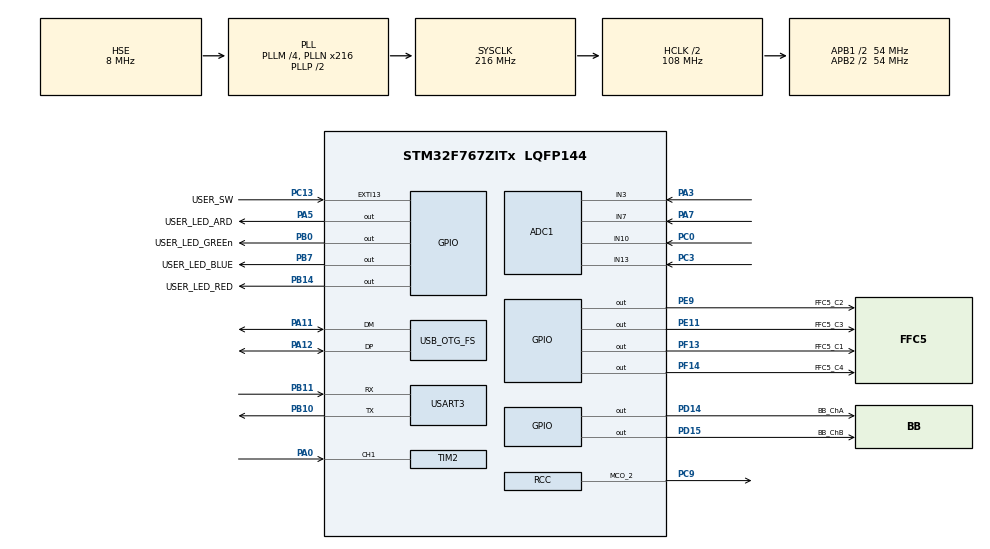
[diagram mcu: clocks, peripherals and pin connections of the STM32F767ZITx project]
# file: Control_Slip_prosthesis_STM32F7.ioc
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ADC1.Channel-0\#ChannelRegularConversion=ADC_CHANNEL_3
ADC1.Channel-4\#ChannelRegularConversion=ADC_CHANNEL_7
ADC1.Channel-5\#ChannelRegularConversion=ADC_CHANNEL_10
ADC1.Channel-6\#ChannelRegularConversion=ADC_CHANNEL_13
ADC1.ContinuousConvMode=ENABLE
ADC1.NbrOfConversion=4
ADC1.NbrOfConversionFlag=1
ADC1.Rank-0\#ChannelRegularConversion=1
ADC1.Rank-4\#ChannelRegularConversion=2
ADC1.Rank-5\#ChannelRegularConversion=3
ADC1.Rank-6\#ChannelRegularConversion=4
ADC1.SamplingTime-0\#ChannelRegularConversion=ADC_SAMPLETIME_480CYCLES
ADC1.SamplingTime-4\#ChannelRegularConversion=ADC_SAMPLETIME_480CYCLES
ADC1.SamplingTime-5\#ChannelRegularConversion=ADC_SAMPLETIME_480CYCLES
ADC1.SamplingTime-6\#ChannelRegularConversion=ADC_SAMPLETIME_480CYCLES
ADC1.ScanConvMode=ADC_SCAN_ENABLE
ADC1.master=1
Mcu.Family=STM32F7
Mcu.Name=STM32F767ZITx
Mcu.Package=LQFP144
NVIC.EXTI15_10_IRQn=true\:5\:0\:true\:false\:true\:true\:true
NVIC.OTG_FS_IRQn=true\:2\:0\:true\:false\:true\:true\:true
NVIC.PriorityGroup=NVIC_PRIORITYGROUP_4
NVIC.TIM1_UP_TIM10_IRQn=true\:2\:0\:true\:false\:true\:true\:true
NVIC.USART3_IRQn=true\:2\:0\:true\:false\:true\:true\:true
PA0/WKUP.Signal=S_TIM2_CH1_ETR
PA1.Signal=ADCx_IN1
PA11.Mode=Device_Only
PA11.Signal=USB_OTG_FS_DM
PA12.Mode=Device_Only
PA12.Signal=USB_OTG_FS_DP
PA13.Mode=Serial_Wire
PA13.Signal=SYS_JTMS-SWDIO
PA14.Mode=Serial_Wire
PA14.Signal=SYS_JTCK-SWCLK
PA3.Signal=ADCx_IN3
PA5.GPIO_Label=USER_LED_ARD
PA5.GPIO_Speed=GPIO_SPEED_FREQ_VERY_HIGH
PA5.PinState=GPIO_PIN_RESET
PA5.Signal=GPIO_Output
PA7.Signal=ADCx_IN7
PB0.GPIO_Label=USER_LED_GREEn
PB0.GPIO_Speed=GPIO_SPEED_FREQ_VERY_HIGH
PB0.Signal=GPIO_Output
PB10.Mode=Asynchronous
PB10.Signal=USART3_TX
PB11.Mode=Asynchronous
PB11.Signal=USART3_RX
PB14.GPIO_Label=USER_LED_RED
PB14.GPIO_Speed=GPIO_SPEED_FREQ_VERY_HIGH
PB14.Signal=GPIO_Output
PB7.GPIO_Label=USER_LED_BLUE
PB7.GPIO_Speed=GPIO_SPEED_FREQ_VERY_HIGH
PB7.Signal=GPIO_Output
PC0.Signal=ADCx_IN10
PC13.GPIO_Label=USER_SW
PC13.GPIO_ModeDefaultEXTI=GPIO_MODE_IT_FALLING
PC13.GPIO_PuPd=GPIO_NOPULL
PC13.Signal=GPXTI13
PC14/OSC32_IN.Mode=LSE-External-Oscillator
PC14/OSC32_IN.Signal=RCC_OSC32_IN
PC15/OSC32_OUT.Mode=LSE-External-Oscillator
PC15/OSC32_OUT.Signal=RCC_OSC32_OUT
PC3.Signal=ADCx_IN13
PC9.Mode=Clock-out-2
PC9.Signal=RCC_MCO_2
PD14.GPIO_Label=BB_ChA
PD14.Signal=GPIO_Output
PD15.GPIO_Label=BB_ChB
PD15.Signal=GPIO_Output
PE11.GPIO_Label=FFC5_C3
PE11.GPIO_Speed=GPIO_SPEED_FREQ_HIGH
PE11.Signal=GPIO_Output
PE9.GPIO_Label=FFC5_C2
PE9.GPIO_Speed=GPIO_SPEED_FREQ_HIGH
PE9.Signal=GPIO_Output
PF13.GPIO_Label=FFC5_C1
PF13.GPIO_Speed=GPIO_SPEED_FREQ_HIGH
PF13.Signal=GPIO_Output
PF14.GPIO_Label=FFC5_C4
PF14.GPIO_Speed=GPIO_SPEED_FREQ_HIGH
PF14.Signal=GPIO_Output
PH0/OSC_IN.Mode=HSE-External-Clock-Source
PH0/OSC_IN.Signal=RCC_OSC_IN
PH1/OSC_OUT.Mode=HSE-External-Clock-Source
PH1/OSC_OUT.Signal=RCC_OSC_OUT
ProjectManager.HeapSize=0x200
ProjectManager.StackSize=0x400
ProjectManager.TargetToolchain=STM32CubeIDE
RCC.AHBCLKDivider=RCC_SYSCLK_DIV2
RCC.AHBFreq_Value=108000000
RCC.APB1CLKDivider=RCC_HCLK_DIV2
RCC.APB1Freq_Value=54000000
RCC.APB1TimFreq_Value=108000000
RCC.APB2CLKDivider=RCC_HCLK_DIV2
RCC.APB2Freq_Value=54000000
RCC.APB2TimFreq_Value=108000000
RCC.CortexFreq_Value=108000000
RCC.HCLKFreq_Value=108000000
RCC.HSE_VALUE=8000000
RCC.HSI_VALUE=16000000
RCC.PLLM=4
RCC.PLLN=216
RCC.PLLQ=9
RCC.RCC_MCO2Source=RCC_MCO2SOURCE_PLLCLK
RCC.RCC_MCODiv1=RCC_MCODIV_4
RCC.RCC_MCODiv2=RCC_MCODIV_5
RCC.SYSCLKFreq_VALUE=216000000
RCC.SYSCLKSource=RCC_SYSCLKSOURCE_PLLCLK
RCC.USBFreq_Value=48000000
RCC.VCOOutputFreq_Value=432000000
SH.ADCx_IN1.0=ADC1_IN1
SH.ADCx_IN10.0=ADC1_IN10,IN10
SH.ADCx_IN13.0=ADC1_IN13,IN13
SH.ADCx_IN3.0=ADC1_IN3,IN3
SH.ADCx_IN7.0=ADC1_IN7,IN7
SH.S_TIM2_CH1_ETR.0=TIM2_CH1,Input_Capture1_from_TI1
TIM1.Period=2-1
TIM1.Prescaler=54000-1
TIM2.Channel-Input_Capture1_from_TI1=TIM_CHANNEL_1
TIM2.Period=255
TIM2.Prescaler=143
USART3.VirtualMode-Asynchronous=VM_ASYNC
USB_DEVICE.CLASS_NAME_FS=CDC
USB_DEVICE.VirtualMode-CDC_FS=Cdc
USB_DEVICE.VirtualModeFS=Cdc_FS
USB_OTG_FS.VirtualMode=Device_Only
VP_TIM1_VS_ClockSourceINT.Mode=Internal
VP_USB_DEVICE_VS_USB_DEVICE_CDC_FS.Mode=CDC_FS
board=custom

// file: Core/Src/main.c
/* USER CODE BEGIN Header */
/**
 ******************************************************************************
 * @file           : main.c
 * @brief          : Main program body
 ******************************************************************************
 * @attention
 *
 * <h2><center>&copy; Copyright (c) 2021 STMicroelectronics.
 * All rights reserved.</center></h2>
 *
 * This software component is licensed by ST under BSD 3-Clause license,
 * the "License"; You may not use this file except in compliance with the
 * License. You may obtain a copy of the License at:
 *                        opensource.org/licenses/BSD-3-Clause
 *
 ******************************************************************************
 */
/* USER CODE END Header */
#include "main.h"
#include "usb_device.h"

/* USER CODE BEGIN Includes */
#include "app.h"
#include "definitions.h"
#include "bebionic.h"
/* USER CODE END Includes */

ADC_HandleTypeDef hadc1;

TIM_HandleTypeDef htim1;
TIM_HandleTypeDef htim2;

UART_HandleTypeDef huart3;

void SystemClock_Config(void);
static void MX_GPIO_Init(void);
static void MX_USART3_UART_Init(void);
static void MX_TIM1_Init(void);
static void MX_ADC1_Init(void);
static void MX_TIM2_Init(void);

int main(void)
{

  /* MCU Configuration--------------------------------------------------------*/

  /* Reset of all peripherals, Initializes the Flash interface and the Systick. */
  HAL_Init();

  /* Configure the system clock */
  SystemClock_Config();

  /* Initialize all configured peripherals */
  MX_GPIO_Init();
  MX_USART3_UART_Init();
  MX_TIM1_Init();
  MX_ADC1_Init();
  MX_USB_DEVICE_Init();
  MX_TIM2_Init();
  /* USER CODE BEGIN 2 */
  app_init(); // Funções de inicialização na pasta app para não misturar

  /* USER CODE END 2 */

  /* Infinite loop */
  /* USER CODE BEGIN WHILE */
  while (1)
  {
	app_controle_bebionic(); // teste para controle da prótese
    // app_loop(); // Funções do loop na pasta app para não misturar
    /* USER CODE END WHILE */

    /* USER CODE BEGIN 3 */
    /*
    HAL_GPIO_TogglePin(GPIOA, GPIO_PIN_5);
    HAL_Delay(1);
    HAL_GPIO_TogglePin(GPIOB, GPIO_PIN_0);
        //HAL_Delay(200);
      HAL_GPIO_TogglePin(GPIOB, GPIO_PIN_7);
         // HAL_Delay(200);
        HAL_GPIO_TogglePin(GPIOB, GPIO_PIN_14);
           // HAL_Delay(200);
        */
  }
  /* USER CODE END 3 */
}

void SystemClock_Config(void)
{
  RCC_OscInitTypeDef RCC_OscInitStruct = {0};
  RCC_ClkInitTypeDef RCC_ClkInitStruct = {0};
  RCC_PeriphCLKInitTypeDef PeriphClkInitStruct = {0};

  /** Configure LSE Drive Capability
  */
  HAL_PWR_EnableBkUpAccess();
  /** Configure the main internal regulator output voltage
  */
  __HAL_RCC_PWR_CLK_ENABLE();
  __HAL_PWR_VOLTAGESCALING_CONFIG(PWR_REGULATOR_VOLTAGE_SCALE3);
  /** Initializes the RCC Oscillators according to the specified parameters
  * in the RCC_OscInitTypeDef structure.
  */
  RCC_OscInitStruct.OscillatorType = RCC_OSCILLATORTYPE_HSE;
  RCC_OscInitStruct.HSEState = RCC_HSE_BYPASS;
  RCC_OscInitStruct.PLL.PLLState = RCC_PLL_ON;
  RCC_OscInitStruct.PLL.PLLSource = RCC_PLLSOURCE_HSE;
  RCC_OscInitStruct.PLL.PLLM = 4;
  RCC_OscInitStruct.PLL.PLLN = 216;
  RCC_OscInitStruct.PLL.PLLP = RCC_PLLP_DIV2;
  RCC_OscInitStruct.PLL.PLLQ = 9;
  RCC_OscInitStruct.PLL.PLLR = 2;
  if (HAL_RCC_OscConfig(&RCC_OscInitStruct) != HAL_OK)
  {
    Error_Handler();
  }
  /** Activate the Over-Drive mode
  */
  if (HAL_PWREx_EnableOverDrive() != HAL_OK)
  {
    Error_Handler();
  }
  /** Initializes the CPU, AHB and APB buses clocks
  */
  RCC_ClkInitStruct.ClockType = RCC_CLOCKTYPE_HCLK|RCC_CLOCKTYPE_SYSCLK
                              |RCC_CLOCKTYPE_PCLK1|RCC_CLOCKTYPE_PCLK2;
  RCC_ClkInitStruct.SYSCLKSource = RCC_SYSCLKSOURCE_PLLCLK;
  RCC_ClkInitStruct.AHBCLKDivider = RCC_SYSCLK_DIV2;
  RCC_ClkInitStruct.APB1CLKDivider = RCC_HCLK_DIV2;
  RCC_ClkInitStruct.APB2CLKDivider = RCC_HCLK_DIV2;

  if (HAL_RCC_ClockConfig(&RCC_ClkInitStruct, FLASH_LATENCY_3) != HAL_OK)
  {
    Error_Handler();
  }
  PeriphClkInitStruct.PeriphClockSelection = RCC_PERIPHCLK_USART3|RCC_PERIPHCLK_CLK48;
  PeriphClkInitStruct.Usart3ClockSelection = RCC_USART3CLKSOURCE_PCLK1;
  PeriphClkInitStruct.Clk48ClockSelection = RCC_CLK48SOURCE_PLL;
  if (HAL_RCCEx_PeriphCLKConfig(&PeriphClkInitStruct) != HAL_OK)
  {
    Error_Handler();
  }
  HAL_RCC_MCOConfig(RCC_MCO2, RCC_MCO2SOURCE_PLLCLK, RCC_MCODIV_5);
}

static void MX_ADC1_Init(void)
{

  ADC_ChannelConfTypeDef sConfig = {0};

  /* USER CODE BEGIN ADC1_Init 1 */
  //--------------------------------------------------------------------------
  // hadc1.Init.NbrOfConversion = 1;
  // COMENTAR CANAIS APÓS
  // if (HAL_ADC_Init(&hadc1) != HAL_OK)
  //--------------------------------------------------------------------------

  /* USER CODE END ADC1_Init 1 */
  /** Configure the global features of the ADC (Clock, Resolution, Data Alignment and number of conversion)
  */
  hadc1.Instance = ADC1;
  hadc1.Init.ClockPrescaler = ADC_CLOCK_SYNC_PCLK_DIV2;
  hadc1.Init.Resolution = ADC_RESOLUTION_12B;
  hadc1.Init.ScanConvMode = ADC_SCAN_ENABLE;
  hadc1.Init.ContinuousConvMode = ENABLE;
  hadc1.Init.DiscontinuousConvMode = DISABLE;
  hadc1.Init.ExternalTrigConvEdge = ADC_EXTERNALTRIGCONVEDGE_NONE;
  hadc1.Init.ExternalTrigConv = ADC_SOFTWARE_START;
  hadc1.Init.DataAlign = ADC_DATAALIGN_RIGHT;
  hadc1.Init.NbrOfConversion = 1; //4;
  hadc1.Init.DMAContinuousRequests = DISABLE;
  hadc1.Init.EOCSelection = ADC_EOC_SINGLE_CONV;
  if (HAL_ADC_Init(&hadc1) != HAL_OK)
  {
    Error_Handler();
  }
//  /** Configure for the selected ADC regular channel its corresponding rank in the sequencer and its sample time.
//  */
//  sConfig.Channel = ADC_CHANNEL_3;
//  sConfig.Rank = ADC_REGULAR_RANK_1;
//  sConfig.SamplingTime = ADC_SAMPLETIME_480CYCLES;
//  if (HAL_ADC_ConfigChannel(&hadc1, &sConfig) != HAL_OK)
//  {
//    Error_Handler();
//  }
//  /** Configure for the selected ADC regular channel its corresponding rank in the sequencer and its sample time.
//  */
//  sConfig.Channel = ADC_CHANNEL_7;
//  sConfig.Rank = ADC_REGULAR_RANK_2;
//  if (HAL_ADC_ConfigChannel(&hadc1, &sConfig) != HAL_OK)
//  {
//    Error_Handler();
//  }
//  /** Configure for the selected ADC regular channel its corresponding rank in the sequencer and its sample time.
//  */
//  sConfig.Channel = ADC_CHANNEL_10;
//  sConfig.Rank = ADC_REGULAR_RANK_3;
//  if (HAL_ADC_ConfigChannel(&hadc1, &sConfig) != HAL_OK)
//  {
//    Error_Handler();
//  }
//  /** Configure for the selected ADC regular channel its corresponding rank in the sequencer and its sample time.
//  */
//  sConfig.Channel = ADC_CHANNEL_13;
//  sConfig.Rank = ADC_REGULAR_RANK_4;
//  if (HAL_ADC_ConfigChannel(&hadc1, &sConfig) != HAL_OK)
//  {
//    Error_Handler();
//  }
//  /* USER CODE BEGIN ADC1_Init 2 */
//
//  /* USER CODE END ADC1_Init 2 */

}

static void MX_TIM1_Init(void)
{

  TIM_ClockConfigTypeDef sClockSourceConfig = {0};
  TIM_MasterConfigTypeDef sMasterConfig = {0};

  htim1.Instance = TIM1;
  htim1.Init.Prescaler = 54000-1;
  htim1.Init.CounterMode = TIM_COUNTERMODE_UP;
  htim1.Init.Period = 2-1;
  htim1.Init.ClockDivision = TIM_CLOCKDIVISION_DIV1;
  htim1.Init.RepetitionCounter = 0;
  htim1.Init.AutoReloadPreload = TIM_AUTORELOAD_PRELOAD_DISABLE;
  if (HAL_TIM_Base_Init(&htim1) != HAL_OK)
  {
    Error_Handler();
  }
  sClockSourceConfig.ClockSource = TIM_CLOCKSOURCE_INTERNAL;
  if (HAL_TIM_ConfigClockSource(&htim1, &sClockSourceConfig) != HAL_OK)
  {
    Error_Handler();
  }
  sMasterConfig.MasterOutputTrigger = TIM_TRGO_RESET;
  sMasterConfig.MasterOutputTrigger2 = TIM_TRGO2_RESET;
  sMasterConfig.MasterSlaveMode = TIM_MASTERSLAVEMODE_DISABLE;
  if (HAL_TIMEx_MasterConfigSynchronization(&htim1, &sMasterConfig) != HAL_OK)
  {
    Error_Handler();
  }

}

static void MX_TIM2_Init(void)
{

  TIM_MasterConfigTypeDef sMasterConfig = {0};
  TIM_IC_InitTypeDef sConfigIC = {0};

  htim2.Instance = TIM2;
  htim2.Init.Prescaler = 143;
  htim2.Init.CounterMode = TIM_COUNTERMODE_UP;
  htim2.Init.Period = 255;
  htim2.Init.ClockDivision = TIM_CLOCKDIVISION_DIV1;
  htim2.Init.AutoReloadPreload = TIM_AUTORELOAD_PRELOAD_DISABLE;
  if (HAL_TIM_IC_Init(&htim2) != HAL_OK)
  {
    Error_Handler();
  }
  sMasterConfig.MasterOutputTrigger = TIM_TRGO_RESET;
  sMasterConfig.MasterSlaveMode = TIM_MASTERSLAVEMODE_DISABLE;
  if (HAL_TIMEx_MasterConfigSynchronization(&htim2, &sMasterConfig) != HAL_OK)
  {
    Error_Handler();
  }
  sConfigIC.ICPolarity = TIM_INPUTCHANNELPOLARITY_RISING;
  sConfigIC.ICSelection = TIM_ICSELECTION_DIRECTTI;
  sConfigIC.ICPrescaler = TIM_ICPSC_DIV1;
  sConfigIC.ICFilter = 0;
  if (HAL_TIM_IC_ConfigChannel(&htim2, &sConfigIC, TIM_CHANNEL_1) != HAL_OK)
  {
    Error_Handler();
  }

}

static void MX_USART3_UART_Init(void)
{

  huart3.Instance = USART3;
  huart3.Init.BaudRate = 115200;
  huart3.Init.WordLength = UART_WORDLENGTH_8B;
  huart3.Init.StopBits = UART_STOPBITS_1;
  huart3.Init.Parity = UART_PARITY_NONE;
  huart3.Init.Mode = UART_MODE_TX_RX;
  huart3.Init.HwFlowCtl = UART_HWCONTROL_NONE;
  huart3.Init.OverSampling = UART_OVERSAMPLING_16;
  huart3.Init.OneBitSampling = UART_ONE_BIT_SAMPLE_DISABLE;
  huart3.AdvancedInit.AdvFeatureInit = UART_ADVFEATURE_NO_INIT;
  if (HAL_UART_Init(&huart3) != HAL_OK)
  {
    Error_Handler();
  }

}

static void MX_GPIO_Init(void)
{
  GPIO_InitTypeDef GPIO_InitStruct = {0};

  /* GPIO Ports Clock Enable */
  __HAL_RCC_GPIOC_CLK_ENABLE();
  __HAL_RCC_GPIOH_CLK_ENABLE();
  __HAL_RCC_GPIOA_CLK_ENABLE();
  __HAL_RCC_GPIOB_CLK_ENABLE();
  __HAL_RCC_GPIOF_CLK_ENABLE();
  __HAL_RCC_GPIOE_CLK_ENABLE();
  __HAL_RCC_GPIOD_CLK_ENABLE();

  /*Configure GPIO pin Output Level */
  HAL_GPIO_WritePin(USER_LED_ARD_GPIO_Port, USER_LED_ARD_Pin, GPIO_PIN_RESET);

  /*Configure GPIO pin Output Level */
  HAL_GPIO_WritePin(GPIOB, USER_LED_GREEn_Pin|USER_LED_RED_Pin|USER_LED_BLUE_Pin, GPIO_PIN_RESET);

  /*Configure GPIO pin Output Level */
  HAL_GPIO_WritePin(GPIOF, FFC5_C1_Pin|FFC5_C4_Pin, GPIO_PIN_RESET);

  /*Configure GPIO pin Output Level */
  HAL_GPIO_WritePin(GPIOE, FFC5_C2_Pin|FFC5_C3_Pin, GPIO_PIN_RESET);

  /*Configure GPIO pin Output Level */
  HAL_GPIO_WritePin(GPIOD, BB_ChA_Pin|BB_ChB_Pin, GPIO_PIN_RESET);

  /*Configure GPIO pin : USER_SW_Pin */
  GPIO_InitStruct.Pin = USER_SW_Pin;
  GPIO_InitStruct.Mode = GPIO_MODE_IT_FALLING;
  GPIO_InitStruct.Pull = GPIO_NOPULL;
  HAL_GPIO_Init(USER_SW_GPIO_Port, &GPIO_InitStruct);

  /*Configure GPIO pin : USER_LED_ARD_Pin */
  GPIO_InitStruct.Pin = USER_LED_ARD_Pin;
  GPIO_InitStruct.Mode = GPIO_MODE_OUTPUT_PP;
  GPIO_InitStruct.Pull = GPIO_NOPULL;
  GPIO_InitStruct.Speed = GPIO_SPEED_FREQ_VERY_HIGH;
  HAL_GPIO_Init(USER_LED_ARD_GPIO_Port, &GPIO_InitStruct);

  /*Configure GPIO pins : USER_LED_GREEn_Pin USER_LED_RED_Pin USER_LED_BLUE_Pin */
  GPIO_InitStruct.Pin = USER_LED_GREEn_Pin|USER_LED_RED_Pin|USER_LED_BLUE_Pin;
  GPIO_InitStruct.Mode = GPIO_MODE_OUTPUT_PP;
  GPIO_InitStruct.Pull = GPIO_NOPULL;
  GPIO_InitStruct.Speed = GPIO_SPEED_FREQ_VERY_HIGH;
  HAL_GPIO_Init(GPIOB, &GPIO_InitStruct);

  /*Configure GPIO pins : FFC5_C1_Pin FFC5_C4_Pin */
  GPIO_InitStruct.Pin = FFC5_C1_Pin|FFC5_C4_Pin;
  GPIO_InitStruct.Mode = GPIO_MODE_OUTPUT_PP;
  GPIO_InitStruct.Pull = GPIO_NOPULL;
  GPIO_InitStruct.Speed = GPIO_SPEED_FREQ_HIGH;
  HAL_GPIO_Init(GPIOF, &GPIO_InitStruct);

  /*Configure GPIO pins : FFC5_C2_Pin FFC5_C3_Pin */
  GPIO_InitStruct.Pin = FFC5_C2_Pin|FFC5_C3_Pin;
  GPIO_InitStruct.Mode = GPIO_MODE_OUTPUT_PP;
  GPIO_InitStruct.Pull = GPIO_NOPULL;
  GPIO_InitStruct.Speed = GPIO_SPEED_FREQ_HIGH;
  HAL_GPIO_Init(GPIOE, &GPIO_InitStruct);

  /*Configure GPIO pins : BB_ChA_Pin BB_ChB_Pin */
  GPIO_InitStruct.Pin = BB_ChA_Pin|BB_ChB_Pin;
  GPIO_InitStruct.Mode = GPIO_MODE_OUTPUT_PP;
  GPIO_InitStruct.Pull = GPIO_NOPULL;
  GPIO_InitStruct.Speed = GPIO_SPEED_FREQ_LOW;
  HAL_GPIO_Init(GPIOD, &GPIO_InitStruct);

  /*Configure GPIO pin : PC9 */
  GPIO_InitStruct.Pin = GPIO_PIN_9;
  GPIO_InitStruct.Mode = GPIO_MODE_AF_PP;
  GPIO_InitStruct.Pull = GPIO_NOPULL;
  GPIO_InitStruct.Speed = GPIO_SPEED_FREQ_LOW;
  GPIO_InitStruct.Alternate = GPIO_AF0_MCO;
  HAL_GPIO_Init(GPIOC, &GPIO_InitStruct);

  /* EXTI interrupt init*/
  HAL_NVIC_SetPriority(EXTI15_10_IRQn, 5, 0);
  HAL_NVIC_EnableIRQ(EXTI15_10_IRQn);

}

void Error_Handler(void)
{
  __disable_irq();
  while (1)
  {
  }
}

/************************ (C) COPYRIGHT STMicroelectronics *****END OF FILE****/
